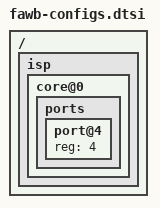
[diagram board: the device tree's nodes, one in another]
#include "../common/isp-csi2.dtsi"
#include "fawb-desers.dtsi"
#include "faw-cameras.dtsi"

/* this board support hdmi input */
/ { 
    isp { core@0 { ports { port@4 {
        reg = <4>;
        //hdmi_isp: endpoint@4 {
        //remote-endpoint = <&hdmi_in>;}; 
    }; }; }; };
};
